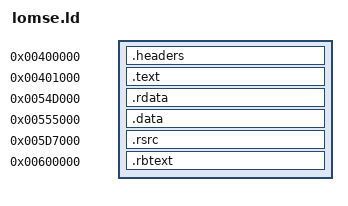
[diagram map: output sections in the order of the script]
/* lomse.exe linker script (NEXT_PHASE step 8).
 *
 * Documents the vanilla MSVC 6 layout for Lords of Magic SE 3.01.
 * ImageBase 0x00400000, entry WinMainCRTStartup at 0x0053c2c0,
 * IAT at 0x0054d000 (888 bytes), import directory at 0x005536f0
 * (260 bytes), resource directory at 0x005d7000.
 *
 * tools/gen_pe.py is the official emitter: lld-link will not produce a
 * byte-identical MSVC 6 header or import name stream, just as llvm-windres
 * is not vanilla-identical for .rsrc (see tools/gen_rsrc.py). This script
 * is the contract the generator (and a later real link) must satisfy.
 *
 * Extra standalone .rb* sections live at 0x00600000 and are not part of
 * the vanilla four-section image; they do not move these addresses.
 */

OUTPUT_FORMAT("pei-i386")
OUTPUT_ARCH(i386)
ENTRY(rb_0053c2c0)

ImageBase     = 0x00400000;
SectionAlign  = 0x1000;
FileAlign     = 0x0200;
IAT_VA        = 0x0054d000;
IAT_SIZE      = 0x378;
IMPORT_DIR_VA = 0x005536f0;
IMPORT_DIR_SZ = 0x104;
RSRC_DIR_VA   = 0x005d7000;
RSRC_DIR_SZ   = 0x980;
ENTRY_VA      = 0x0053c2c0;

SECTIONS
{
  /* PE headers occupy RVAs 0x0–0x1000 (SizeOfHeaders 0x400, aligned). */
  .headers ImageBase : {
    /* DOS stub + Rich + COFF/optional header + 4 section table entries,
       generated by tools/gen_pe.py (not copied from vanilla). */
  } :headers

  .text 0x00401000 : {
    *(.text)
    /* Implemented entries are 5-byte jmp into the rb image; rawtext
       ranges (tables, padding, mid-entry tails) come from src/rawtext.
       The 33 import thunks may be *(.text.iat_thunks) from thunks.s
       or left as the original ff 25 <IAT> bytes. */
  }

  .rdata 0x0054d000 : {
    /* IAT: 210 slots + 12 DLL NULLs = 888 bytes, then the rest of
       sourced .rdata, with the import directory / ILT / hint-names
       at the tail (IMPORT_DIR_VA). */
    *(.idata$5)          /* IAT */
    *(.rdata)
    . = IMPORT_DIR_VA - 0x00400000;
    *(.idata$2)          /* import descriptors */
    *(.idata$4)          /* ILT */
    *(.idata$6)          /* hint/name + DLL name strings */
  }

  .data 0x00555000 : {
    *(.data)
    /* Initialized slice is 143872 bytes; BSS tail is 387388 bytes
       of labeled .zero (NOBITS conceptually, but this section is
       the MSVC .data with a large virtual size). */
    *(.bss)
  }

  .rsrc 0x005d7000 : {
    *(.rsrc)
  }

  /* Standalone rebuilt bodies only (not in vanilla): */
  .rbtext 0x00600000 : { *(.rbtext) }
}

ASSERT(IAT_VA == 0x0054d000, "IAT must stay at 0x0054d000")
ASSERT(ENTRY_VA == 0x0053c2c0, "entry must stay WinMainCRTStartup")
